# MIMXRT685S_cm33 register map
Vendor: nxp.com; File version: 1.0
CPU: CM33 r2p0, little endian, MPU, FPU, VTOR, 3 interrupt priority bits
Registers are 32-bit, read-write, reset 0x0 unless marked. A register's access mark holds for its fields unless they carry their own. Offsets are from the block's base; [hi:lo] are bit positions; lines under a group give offsets from that group; {n}, {i} and the like mark numbered series; 'fields as' and 'values as' point back to an identical list.

## INPUTMUX — LPC_Next0 Peripheral Input Multiplexers Controller
Base 0x40026000
{0x0+4i} SCT0_IN_SEL{i} (i=0..6) reset 0x1F — SCT Peripheral Input Multiplexers N
  [4:0] SCT_IN_SEL — SCT0 Input(n) Selection. 24:1 Selection for each. . .
    {v}=SCT0_PIN_INP{v} (v=0..7); {v}=CT32BIT{v-8}_MAT0 (v=8..12); 13=ADCIRQ; 14=GPIOINT_BMATCH; 15=USB1_FRAME_TOGGLE; 16=CMP0_OUT; 17=SHARED_I2S0_SCLK; 18=SHARED_I2S1_SCLK; 19=SHARED_I2S0_WS; 20=SHARED_I2S1_WS; 21=MCLK; 22=ARM_TXEV; 23=DEBUG_HALTED
{0x100+4i} PINT_SEL{i} (i=0..7) reset 0x7F (reset mask 0x7F) — GPIO Pin Input Multiplexer N
  [7:0] PINT_SEL — Port Input (PIOx.y) 64 to 8 Mux Select. . . Pin number select for pin interrupt or pattern match engine input. (For PIOx_y: INTPIN = (x * 32) + y. PIO0_0 to PIO1_31 correspond to numbers 0 to 63.
{0x140+4i} DSP_INT_SEL[{i}] (i=0..26) reset 0x3F — DSP Interrupt Input Multiplexers N
  [5:0] DSP_INT_SEL — DSP Input(n) Selection. 34:1 Selection for each. . .
    {v}=FLEXCOMM{v} (v=0..7); {v}=GPIO_INT0_IRQ{v-8} (v=8..15); 16=NSHSGPIO_INT0; 17=NSHSGPIO_INT1; 18=WDT1; 19=DMAC0; 20=DMAC1; 21=MU; 22=UTICK0; 23=MRT0; 24=OS_EVENT_TIMER_or_OS_EVENT_WAKEUP; {v}=CT32BIT{v-25} (v=25..29); 30=RTC_LITE0_ALARM_or_RTC_LITE0_WAKEUP; 31=I3C0; 32=DMIC0; 33=HWVAD0; 34=FLEXSPI
{0x200+4i} DMAC0_ITRIG_SEL[{i}] (i=0..32) reset 0x1F — DMAC0 Input Trigger Multiplexers N
  [4:0] DMA0_ITRIG_SEL — DMA Input Triggers(n) Selection. 22:1 Selection for each. . .
    {v}=NSGPIOPINT0_INT{v} (v=0..3); 4=CT32BIT0_DMAREQ_M0; 5=CT32BIT0_DMAREQ_M1; 6=CT32BIT1_DMAREQ_M0; 7=CT32BIT1_DMAREQ_M1; 8=CT32BIT2_DMAREQ_M0; 9=CT32BIT2_DMAREQ_M1; 10=CT32BIT3_DMAREQ_M0; 11=CT32BIT3_DMAREQ_M1; 12=CT32BIT4_DMAREQ_M0; 13=CT32BIT4_DMAREQ_M1; 14=DMAC0_TRIGOUT_A; 15=DMAC0_TRIGOUT_B; 16=DMAC0_TRIGOUT_C; 17=DMAC0_TRIGOUT_D; 18=SCT0_DMA0; 19=SCT0_DMA1; 20=HASHCRYPT_OUT_DMA; 21=ACMP_DMA; 24=ADC_DMAC; 28=FLEXSPI_RX; 29=FLEXSPI_TX
{0x300+4i} DMAC0_OTRIG_SEL{i} (i=0..3) reset 0x3F — DMAC0 Output Trigger Multiplexers N
  [5:0] DMAC0_OTRIG_SEL — DMAC0 Output Triggers Select for A, B, C, D IE.,DMAC0_OTRIG_A, DMAC0_OTRIG_B, DMAC0_OTRIG_C, DMAC0_OTRIG_D DMA0 Output Triggers(n) Selection. 32:1 Selection for each. . .
    {v}=DMAC0_OTRIG_CH{v} (v=0..32)
{0x400+4i} DMAC1_ITRIG_SEL[{i}] (i=0..32) reset 0x1F — DMAC1 Input Trigger Multiplexers N
  [4:0] DMA1_ITRIG_SEL — DMA Input Triggers(n) Selection. 18:1 Selection for each. . .
    {v}=NSGPIOPINT0_INT{v} (v=0..3); 4=CT32BIT0_DMAREQ_M0; 5=CT32BIT0_DMAREQ_M1; 6=CT32BIT1_DMAREQ_M0; 7=CT32BIT1_DMAREQ_M1; 8=CT32BIT2_DMAREQ_M0; 9=CT32BIT2_DMAREQ_M1; 10=CT32BIT3_DMAREQ_M0; 11=CT32BIT3_DMAREQ_M1; 12=CT32BIT4_DMAREQ_M0; 13=CT32BIT4_DMAREQ_M1; 14=DMAC1_TRIGOUT_A; 15=DMAC1_TRIGOUT_B; 16=DMAC1_TRIGOUT_C; 17=DMAC1_TRIGOUT_D (DMAC0_TRIGOUT_D); 18=SCT0_DMAC0; 19=SCT0_DMAC1; 20=HASHCRYPT_OUT_DMA; 21=ACMP_DMA; 24=ADC_DMAC; 28=FLEXSPI_RX; 29=FLEXSPI_TX
{0x500+4i} DMAC1_OTRIG_SEL{i} (i=0..3) reset 0x3F — DMAC1 Output Trigger Multiplexers N
  [5:0] DMAC1_OTRIG_SEL — DMA1 Output Triggers Select for A, B, C, D IE., DMA1_OTRIG_A, DMA1_OTRIG_B, DM1_OTRIG_C, DMA1_OTRIG_D DMA0 Output Triggers(n) Selection. 32:1 Selection for each. . .
    {v}=DMAC1_OTRIG_CH{v} (v=0..32)
{0x600+0x10*i} CT32BIT_CAP_SEL[{i}] (i=0..4) group — CT32BITn Counter Timer Capture Trigger Multiplexers
  {0x0+4j} CT32BIT_CAP_SEL{j} (j=0..3) reset 0x1F — CT32BIT N Counter Timer Capture Trigger Multiplexers M
    [4:0] CAPn_SEL — Counter Timer m, Capture Port Input n 19:1 Mux Select. . .
      {v}=CT_INP{v} (v=0..15); 16=SHARED_I2S0_WS; 17=SHARED_I2S1_WS; 18=USB1_FRAME_TOGGLE
{0x700+4i} FMEASURE_CH_SEL{i} (i=0..1) reset 0x1F — Frequency Measurement Input Channel Multiplexers
  [4:0] FMEASURE_SEL — Frequency Measure Channel n Selection 7:1 Mux Select. . .
    0=XTALIN; 1=SFRO; 2=FFRO; 3=LPOSC (Low Power Oscillator Clock (LPOSC)); 4=RTC_32KHz_OSC; 5=MAIN_SYS_CLOCK; 6=FREQME_GPIO_CLK
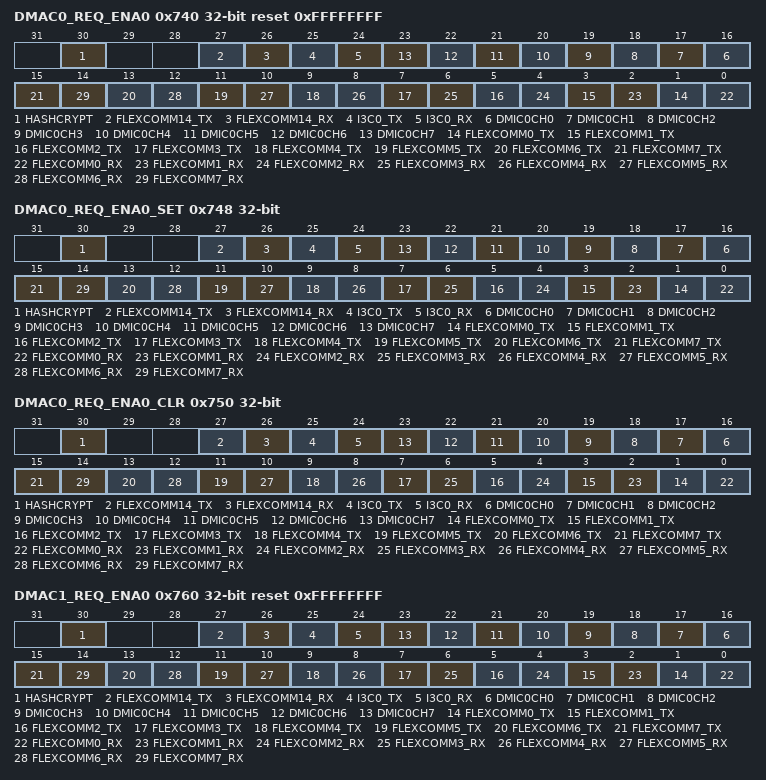
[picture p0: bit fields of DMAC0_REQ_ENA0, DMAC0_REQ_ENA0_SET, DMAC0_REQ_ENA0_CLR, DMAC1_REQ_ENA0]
0x740 DMAC0_REQ_ENA0 reset 0xFFFFFFFF — DMAC0 request enable 0
  [all] fields
    0=DISABLED; 1=ENABLED
  [30] HASHCRYPT — hash enable
  [27] FLEXCOMM14_TX — FLEXCOMM14 TX enable
  [26] FLEXCOMM14_RX — FLEXCOMM14 RX enable
  [25] I3C0_TX — I3C TX enable
  [24] I3C0_RX — I3C RX enable
  [n+16] DMIC0CH{n} (n=0..7) — DMIC0 channel {n} enable
  [2n+1] FLEXCOMM{n}_TX (n=0..7) — FLEXCOMM{n} TX enable
  [2n] FLEXCOMM{n}_RX (n=0..7) — FLEXCOMM{n} RX enable
0x748 DMAC0_REQ_ENA0_SET reset not defined — DMAC0 request enable set 0
  [all] fields
    0=NO_EFFECT; 1=SET_ENA0_BIT (Sets the ENA0 Bit)
  [30] HASHCRYPT wo — Hash enable set
  [27] FLEXCOMM14_TX wo — FLEXCOMM15 RX enable set
  [26] FLEXCOMM14_RX wo — FLEXCOMM14 TX enable set
  [25] I3C0_TX wo — I3C TX enable set
  [24] I3C0_RX wo — I3C RX enable set
  [n+16] DMIC0CH{n} wo (n=0..7) — DMIC0 channel {n} enable set
  [2n+1] FLEXCOMM{n}_TX wo (n=0..7) — FLEXCOMM{n} TX enable set
  [2n] FLEXCOMM{n}_RX wo (n=0..7) — FLEXCOMM{n} RX enable set
0x750 DMAC0_REQ_ENA0_CLR reset not defined — DMAC0 request enable clear 0
  [all] fields
    0=NO_EFFECT; 1=CLR_ENA0_BIT (Clears the ENA0 Bit)
  [30] HASHCRYPT wo — Hash enable clear
  [27] FLEXCOMM14_TX wo — FLEXCOMM14 TX enable clear
  [26] FLEXCOMM14_RX wo — FLEXCOMM14 RX enable clear
  [25] I3C0_TX wo — I3C TX enable clear
  [24] I3C0_RX wo — I3C RX enable clear
  [n+16] DMIC0CH{n} wo (n=0..7) — DMIC0 channel {n} enable clear
  [2n+1] FLEXCOMM{n}_TX wo (n=0..7) — FLEXCOMM{n} TX enable clear
  [2n] FLEXCOMM{n}_RX wo (n=0..7) — FLEXCOMM{n} RX enable clear
0x760 DMAC1_REQ_ENA0 reset 0xFFFFFFFF — DMAC1 request enable 0
  fields as DMAC0_REQ_ENA0
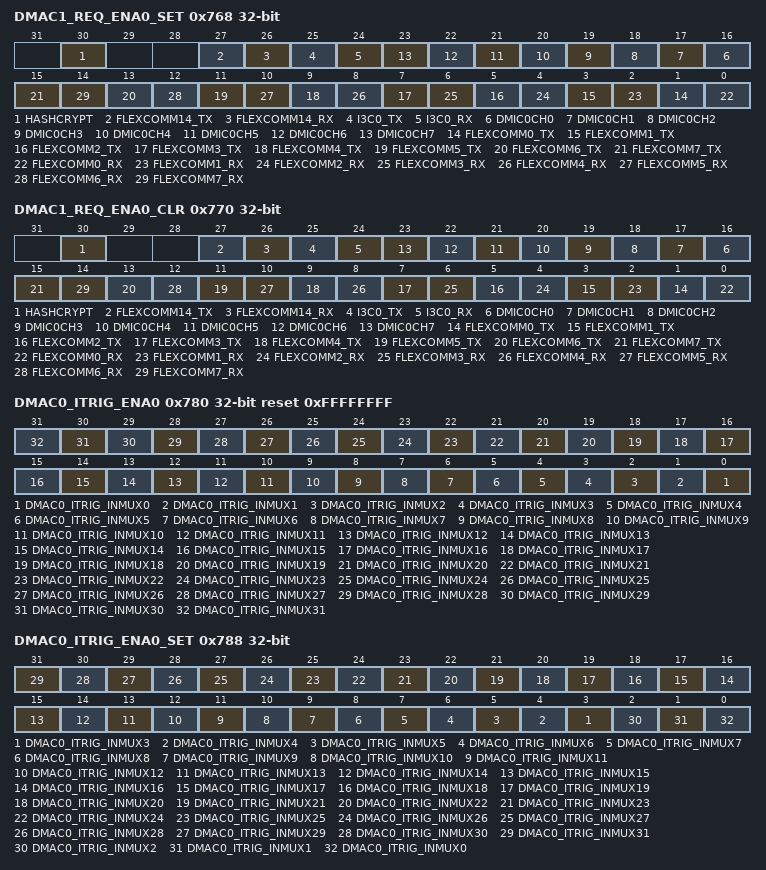
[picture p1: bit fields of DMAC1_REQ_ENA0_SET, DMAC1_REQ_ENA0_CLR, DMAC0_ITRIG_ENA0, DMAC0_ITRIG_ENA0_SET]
0x768 DMAC1_REQ_ENA0_SET reset not defined — DMAC1 request enable set 0
  fields as DMAC0_REQ_ENA0_SET
0x770 DMAC1_REQ_ENA0_CLR reset not defined — DMAC1 request enable clear 0
  fields as DMAC0_REQ_ENA0_CLR
0x780 DMAC0_ITRIG_ENA0 reset 0xFFFFFFFF — DMAC0 input trigger enable 0
  [all] fields
    0=DISABLED; 1=ENABLED
  [n] DMAC0_ITRIG_INMUX{n} (n=0..31) — DMAC0 input trigger inmux {n} enable
0x788 DMAC0_ITRIG_ENA0_SET wo reset not defined — DMAC0 input trigger enable set 0
  [n] DMAC0_ITRIG_INMUX{n} (n=3..31) — DMAC0 input trigger inmux {n} enable set
    0=NO_EFFECT; 1=SET_ENA0_BIT (Sets the ENA0 Bit)
  [2] DMAC0_ITRIG_INMUX2 — DMAC0 input trigger inmux 2 enable set
  [1] DMAC0_ITRIG_INMUX1 — DMAC0 input trigger inmux 1 enable set
    0=NO_EFFECT; 1=SET_ENA0_BIT (Sets the ENA0 Bit)
  [0] DMAC0_ITRIG_INMUX0 — DMAC0 input trigger inmux 0 enable set
    0=NO_EFFECT; 1=SET_ENA0_BIT (Sets the ENA0 Bit)
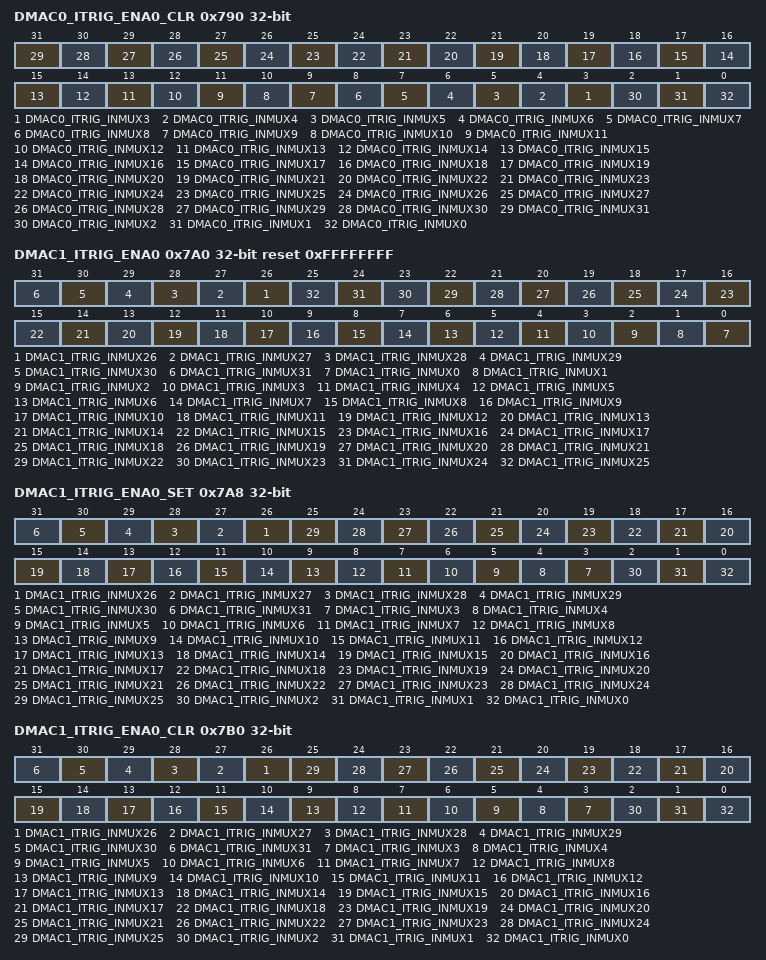
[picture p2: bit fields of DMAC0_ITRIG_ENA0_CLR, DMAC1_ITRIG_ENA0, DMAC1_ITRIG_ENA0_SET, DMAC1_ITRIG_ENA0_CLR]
0x790 DMAC0_ITRIG_ENA0_CLR wo reset not defined — DMAC0 input trigger enable clear 0
  [n] DMAC0_ITRIG_INMUX{n} (n=3..31) — DMAC0 input trigger inmux {n} enable clear
    0=NO_EFFECT; 1=CLR_ENA0_BIT (clears the ENA0 Bit)
  [2] DMAC0_ITRIG_INMUX2 — DMAC0 input trigger inmux 2 enable clear
  [1] DMAC0_ITRIG_INMUX1 — DMAC0 input trigger inmux 1 enable clear
    0=NO_EFFECT; 1=CLR_ENA0_BIT (clears the ENA0 Bit)
  [0] DMAC0_ITRIG_INMUX0 — DMAC0 input trigger inmux 0 enable clear
    0=NO_EFFECT; 1=CLR_ENA0_BIT (clears the ENA0 Bit)
0x7A0 DMAC1_ITRIG_ENA0 reset 0xFFFFFFFF — DMAC1 input trigger enable 0
  [all] fields
    0=DISABLED; 1=ENABLED
  [n] DMAC1_ITRIG_INMUX{n} (n=26..31) — DMAC1 input trigger inmux 25 enable
  [n] DMAC1_ITRIG_INMUX{n} (n=0..25) — DMAC1 input trigger inmux {n} enable
0x7A8 DMAC1_ITRIG_ENA0_SET wo reset not defined — DMAC1 input trigger enable set 0
  [n] DMAC1_ITRIG_INMUX{n} (n=26..31) — DMAC1 input trigger inmux 25 enable set
    0=NO_EFFECT; 1=SET_ENA0_BIT (Sets the ENA0 Bit)
  [n] DMAC1_ITRIG_INMUX{n} (n=3..25) — DMAC1 input trigger inmux {n} enable set
    0=NO_EFFECT; 1=SET_ENA0_BIT (Sets the ENA0 Bit)
  [2] DMAC1_ITRIG_INMUX2 — DMAC1 input trigger inmux 2 enable set
  [1] DMAC1_ITRIG_INMUX1 — DMAC1 input trigger inmux 1 enable set
    0=NO_EFFECT; 1=SET_ENA0_BIT (Sets the ENA0 Bit)
  [0] DMAC1_ITRIG_INMUX0 — DMAC1 input trigger inmux 0 enable set
    0=NO_EFFECT; 1=SET_ENA0_BIT (Sets the ENA0 Bit)
0x7B0 DMAC1_ITRIG_ENA0_CLR wo reset not defined — DMAC1 input trigger enable clear 0
  [n] DMAC1_ITRIG_INMUX{n} (n=26..31) — DMAC1 input trigger inmux 25 enable clear
    0=NO_EFFECT; 1=CLR_ENA0_BIT (clears the ENA0 Bit)
  [n] DMAC1_ITRIG_INMUX{n} (n=3..25) — DMAC1 input trigger inmux {n} enable clear
    0=NO_EFFECT; 1=CLR_ENA0_BIT (clears the ENA0 Bit)
  [2] DMAC1_ITRIG_INMUX2 — DMAC1 input trigger inmux 2 enable clear
  [1] DMAC1_ITRIG_INMUX1 — DMAC1 input trigger inmux 1 enable clear
    0=NO_EFFECT; 1=CLR_ENA0_BIT (clears the ENA0 Bit)
  [0] DMAC1_ITRIG_INMUX0 — DMAC1 input trigger inmux 0 enable clear
    0=NO_EFFECT; 1=CLR_ENA0_BIT (clears the ENA0 Bit)
